# nrf5340_application register map
Vendor: Nordic Semiconductor; Series: nrf53; File version: 1
CPU: CM33 r0p4, little endian, MPU, FPU, 3 interrupt priority bits, 69 interrupts
Registers are 32-bit, read-write, reset 0x0 unless marked. A register's access mark holds for its fields unless they carry their own. Offsets are from the block's base; [hi:lo] are bit positions; {n}, {i} and the like mark numbered series.

## EGU0_NS — Event generator unit 0
Base 0x4001B000
Same registers: EGU1_NS 0x4001C000, EGU2_NS 0x4001D000, EGU3_NS 0x4001E000, EGU4_NS 0x4001F000, EGU5_NS 0x40020000, EGU0_S 0x5001B000, EGU1_S 0x5001C000, EGU2_S 0x5001D000, EGU3_S 0x5001E000, EGU4_S 0x5001F000, EGU5_S 0x50020000
{0x0+4i} TASKS_TRIGGER[{i}] (i=0..15) wo — Description collection: Trigger n for triggering the corresponding TRIGGERED[n] event
  [0] TASKS_TRIGGER — Trigger n for triggering the corresponding TRIGGERED[n] event
    1=Trigger task
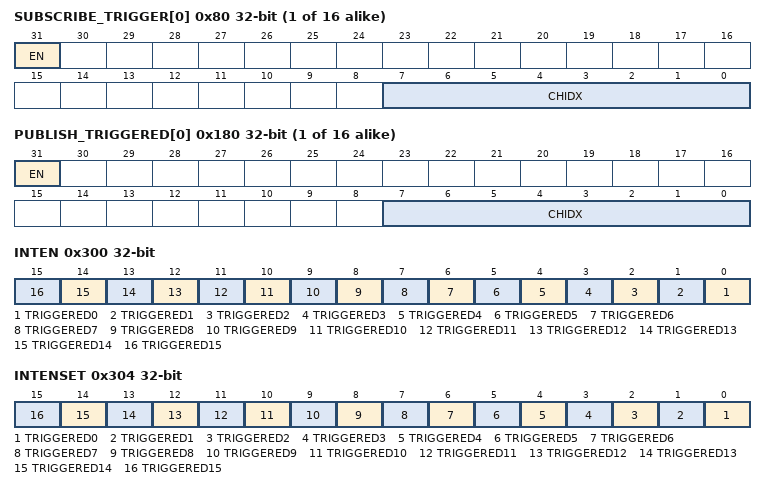
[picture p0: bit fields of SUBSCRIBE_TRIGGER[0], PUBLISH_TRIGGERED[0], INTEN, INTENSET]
{0x80+4i} SUBSCRIBE_TRIGGER[{i}] (i=0..15) — Description collection: Subscribe configuration for task TRIGGER[n]
  [31] EN
    0=Disabled (Disable subscription); 1=Enabled (Enable subscription)
  [7:0] CHIDX — DPPI channel that task TRIGGER[n] will subscribe to
{0x100+4i} EVENTS_TRIGGERED[{i}] (i=0..15) — Description collection: Event number n generated by triggering the corresponding TRIGGER[n] task
  [0] EVENTS_TRIGGERED — Event number n generated by triggering the corresponding TRIGGER[n] task
    0=NotGenerated (Event not generated); 1=Generated (Event generated)
{0x180+4i} PUBLISH_TRIGGERED[{i}] (i=0..15) — Description collection: Publish configuration for event TRIGGERED[n]
  [31] EN
    0=Disabled (Disable publishing); 1=Enabled (Enable publishing)
  [7:0] CHIDX — DPPI channel that event TRIGGERED[n] will publish to.
0x300 INTEN — Enable or disable interrupt
  [all] fields
    0=Disabled; 1=Enabled
  [n] TRIGGERED{n} (n=0..15) — Enable or disable interrupt for event TRIGGERED[{n}]
0x304 INTENSET — Enable interrupt
  [all] fields
    on read: 0=Disabled (Read: Disabled); 1=Enabled (Read: Enabled) | on write: 1=Set (Enable)
  [n] TRIGGERED{n} (n=0..15) — Write '1' to enable interrupt for event TRIGGERED[{n}]
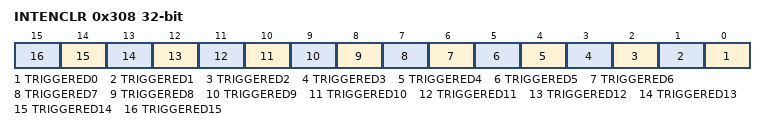
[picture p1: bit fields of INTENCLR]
0x308 INTENCLR — Disable interrupt
  [all] fields
    on read: 0=Disabled (Read: Disabled); 1=Enabled (Read: Enabled) | on write: 1=Clear (Disable)
  [n] TRIGGERED{n} (n=0..15) — Write '1' to disable interrupt for event TRIGGERED[{n}]

## IPC_NS — Interprocessor communication 0
Base 0x4002A000
Same registers: IPC_S 0x5002A000
{0x0+4i} TASKS_SEND[{i}] (i=0..15) wo — Description collection: Trigger events on IPC channel enabled in SEND_CNF[n]
  [0] TASKS_SEND — Trigger events on IPC channel enabled in SEND_CNF[n]
    1=Trigger task
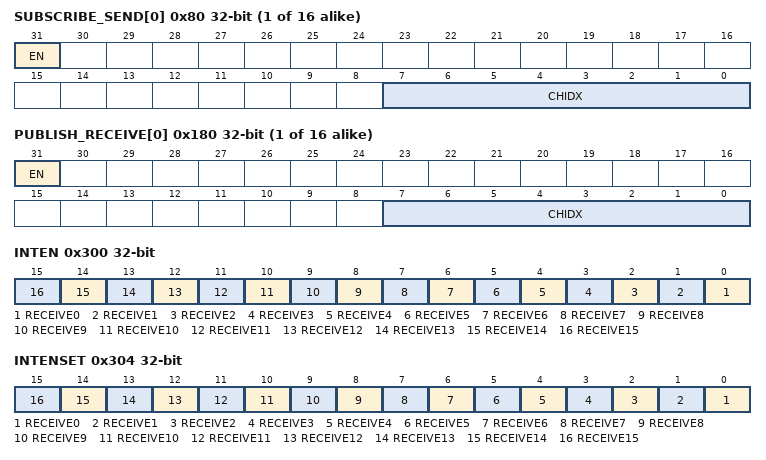
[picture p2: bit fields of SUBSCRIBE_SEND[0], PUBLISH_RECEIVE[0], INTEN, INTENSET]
{0x80+4i} SUBSCRIBE_SEND[{i}] (i=0..15) — Description collection: Subscribe configuration for task SEND[n]
  [31] EN
    0=Disabled (Disable subscription); 1=Enabled (Enable subscription)
  [7:0] CHIDX — DPPI channel that task SEND[n] will subscribe to
{0x100+4i} EVENTS_RECEIVE[{i}] (i=0..15) — Description collection: Event received on one or more of the enabled IPC channels in RECEIVE_CNF[n]
  [0] EVENTS_RECEIVE — Event received on one or more of the enabled IPC channels in RECEIVE_CNF[n]
    0=NotGenerated (Event not generated); 1=Generated (Event generated)
{0x180+4i} PUBLISH_RECEIVE[{i}] (i=0..15) — Description collection: Publish configuration for event RECEIVE[n]
  [31] EN
    0=Disabled (Disable publishing); 1=Enabled (Enable publishing)
  [7:0] CHIDX — DPPI channel that event RECEIVE[n] will publish to.
0x300 INTEN — Enable or disable interrupt
  [all] fields
    0=Disabled; 1=Enabled
  [n] RECEIVE{n} (n=0..15) — Enable or disable interrupt for event RECEIVE[{n}]
0x304 INTENSET — Enable interrupt
  [all] fields
    on read: 0=Disabled (Read: Disabled); 1=Enabled (Read: Enabled) | on write: 1=Set (Enable)
  [n] RECEIVE{n} (n=0..15) — Write '1' to enable interrupt for event RECEIVE[{n}]
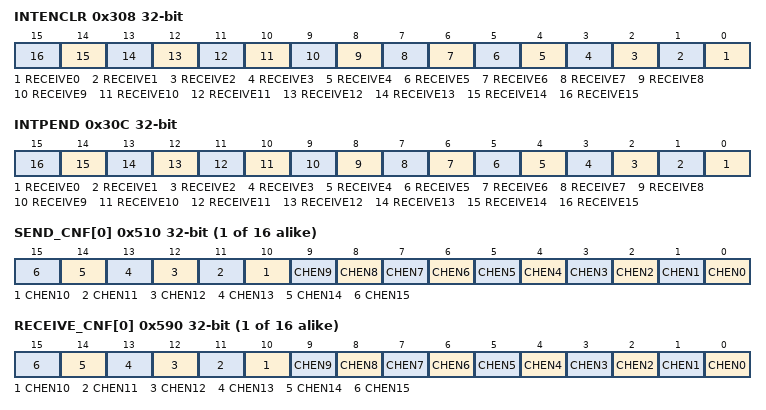
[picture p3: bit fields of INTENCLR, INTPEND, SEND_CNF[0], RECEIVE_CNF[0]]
0x308 INTENCLR — Disable interrupt
  [all] fields
    on read: 0=Disabled (Read: Disabled); 1=Enabled (Read: Enabled) | on write: 1=Clear (Disable)
  [n] RECEIVE{n} (n=0..15) — Write '1' to disable interrupt for event RECEIVE[{n}]
0x30C INTPEND ro — Pending interrupts
  [all] fields
    on read: 0=NotPending (Read: Not pending); 1=Pending (Read: Pending)
  [n] RECEIVE{n} (n=0..15) — Read pending status of interrupt for event RECEIVE[{n}]
{0x510+4i} SEND_CNF[{i}] (i=0..15) — Description collection: Send event configuration for TASKS_SEND[n]
  [all] fields
    0=Disable broadcast; 1=Enable broadcast
  [n] CHEN{n} (n=0..15) — Enable broadcasting on IPC channel {n}
{0x590+4i} RECEIVE_CNF[{i}] (i=0..15) — Description collection: Receive event configuration for EVENTS_RECEIVE[n]
  [all] fields
    0=Disable events; 1=Enable events
  [n] CHEN{n} (n=0..15) — Enable subscription to IPC channel {n}
{0x610+4i} GPMEM[{i}] (i=0..1) — Description collection: General purpose memory
  [31:0] GPMEM — General purpose memory
